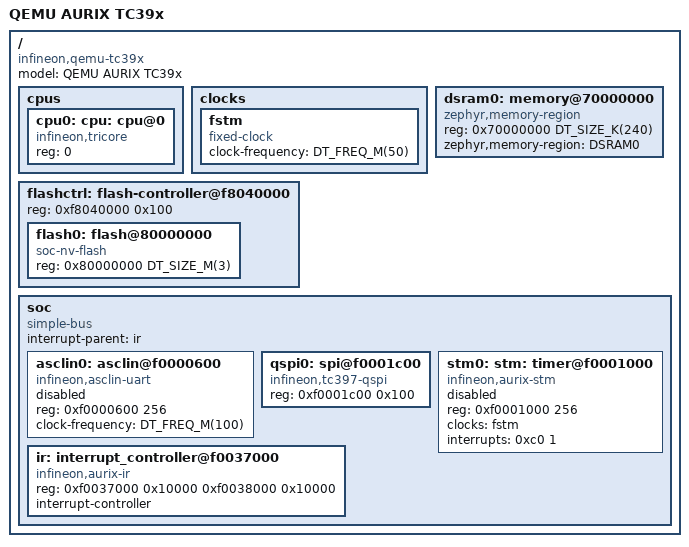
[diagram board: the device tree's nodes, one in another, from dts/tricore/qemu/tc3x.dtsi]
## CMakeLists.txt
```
# SPDX-License-Identifier: GPL-2.0-or-later
cmake_minimum_required(VERSION 3.20.0)
find_package(Zephyr REQUIRED HINTS $ENV{ZEPHYR_BASE})
project(vmcu)
target_include_directories(app PRIVATE include)
target_sources(app PRIVATE src/main.c lib/protocol.c lib/safety.c)
target_include_directories(app PRIVATE ${ZEPHYR_BASE}/drivers/can)
target_sources(app PRIVATE drivers/can_tc397.c src/vehicle_can.c lib/can_policy.c)

if(CONFIG_VMCU_SAFETY_SPI)
  target_sources(app PRIVATE drivers/spi_tc397.c)
endif()
```

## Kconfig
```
# SPDX-License-Identifier: GPL-2.0-or-later
mainmenu "Apollo TC397 vMCU"
# NUM_IRQS counts SRC entries, not the 256 CPU priority vectors.
config NUM_IRQS
    default 512 if SOC_QEMU_TC3X
config CAN_TC397
    bool "TC397 CAN0 node0"
    default y
    depends on CAN
    select CAN_MCAN
config VMCU_SAFETY_SPI
    bool "Use QSPI0 for SI safety transport"
    default n
    select SPI
source "Kconfig.zephyr"
```

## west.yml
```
# SPDX-License-Identifier: Apache-2.0
# Independent vMCU source pin; the Apollo Safety Island checkout stays unchanged.
manifest:
  version: "1.2"
  projects:
    - name: zephyr
      url: https://github.com/zephyrproject-rtos/zephyr
      revision: 894020886d647a5f9b8a58bdf2cb8c211a62716b
      path: zephyr
  self:
    path: zephyr_vmcu_src
```

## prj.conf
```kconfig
CONFIG_SERIAL=y
CONFIG_CONSOLE=y
CONFIG_UART_CONSOLE=y
CONFIG_PRINTK=y
CONFIG_SHELL=y
CONFIG_SHELL_BACKEND_SERIAL=y
CONFIG_SHELL_BACKEND_SERIAL_INTERRUPT_DRIVEN=n
CONFIG_SHELL_PROMPT_UART="vmcu> "
CONFIG_SHELL_STACK_SIZE=4096
CONFIG_MAIN_STACK_SIZE=4096
CONFIG_SYSTEM_WORKQUEUE_STACK_SIZE=2048
CONFIG_LOG=n
CONFIG_BOOT_BANNER=y
CONFIG_CAN=y
CONFIG_CAN_FD_MODE=y
CONFIG_SHELL_CMD_BUFF_SIZE=256
CONFIG_SHELL_BACKEND_SERIAL_RX_RING_BUFFER_SIZE=256
```

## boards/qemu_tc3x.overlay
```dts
/* SPDX-License-Identifier: Apache-2.0 */

/* CPU0, memory, STM0 and polling ASCLIN driver come from upstream qemu_tc3x. */
/ {
	aliases {
		vmcu-link = &asclin0;
		vmcu-safety = &asclin2;
		vmcu-port = &port0;
		vmcu-can = &can0;
	};
	chosen {
		zephyr,console = &asclin1;
		zephyr,shell-uart = &asclin1;
	};
	soc {
		can0: can@f0208200 {
			compatible = "infineon,tc397-mcan";
			reg = <0xf0208200 0x100>, <0xf0200000 0x8000>,
			      <0xf0208000 0x100>, <0xf0208100 0x100>;
			reg-names = "m_can", "message_ram", "common", "node";
			interrupts = <0x16c 13>, <0x16d 14>;
			interrupt-names = "int0", "int1";
			clock-frequency = <100000000>;
			bitrate = <500000>;
			bitrate-data = <2000000>;
			bosch,mram-cfg = <0 8 4 8 0 0 8 8>;
			status = "okay";
		};
		asclin2: asclin@f0000800 {
			compatible = "infineon,asclin-uart";
			reg = <0xf0000800 0x100>;
			clock-frequency = <100000000>;
			current-speed = <115200>;
			status = "okay";
		};
		/* Register-level TC397 PORT0 subset; no alternate-function/IRQ claims. */
		port0: gpio@f003a000 {
			compatible = "infineon,tc397-port";
			reg = <0xf003a000 0x100>;
			status = "okay";
		};
		asclin1: asclin@f0000700 {
			compatible = "infineon,asclin-uart";
			reg = <0xf0000700 0x100>;
			clock-frequency = <100000000>;
			current-speed = <115200>;
			status = "okay";
		};
	};
};

&asclin0 {
	current-speed = <115200>;
	status = "okay";
};
```

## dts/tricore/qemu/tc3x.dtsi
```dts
/*
 * SPDX-FileCopyrightText: Copyright (c) 2026 Infineon Technologies AG,
 * SPDX-FileCopyrightText: or an affiliate of Infineon Technologies AG. All rights reserved.
 * SPDX-FileCopyrightText: Copyright (c) 2026 Linumiz
 *
 * SPDX-License-Identifier: Apache-2.0
 */

#include <mem.h>
#include <freq.h>
#include <skeleton.dtsi>

/ {
	model = "QEMU AURIX TC39x";
	compatible = "infineon,qemu-tc39x";

	cpus {
		#address-cells = <1>;
		#size-cells = <0>;

		cpu0: cpu: cpu@0 {
			compatible = "infineon,tricore", "infineon,tc162";
			reg = <0>;
		};
	};

	clocks {
		fstm: fstm {
			compatible = "fixed-clock";
			clock-frequency = <DT_FREQ_M(50)>;
			#clock-cells = <0>;
		};
	};

	flashctrl: flash-controller@f8040000 {
		reg = <0xf8040000 0x100>;
		ranges;
		#address-cells = <1>;
		#size-cells = <1>;

		flash0: flash@80000000 {
			compatible = "soc-nv-flash";
			reg = <0x80000000 DT_SIZE_M(3)>;
			ranges = <0x0 0x80000000 DT_SIZE_M(3)>;
			#address-cells = <1>;
			#size-cells = <1>;
		};
	};

	dsram0: memory@70000000 {
		compatible = "zephyr,memory-region", "mmio-sram";
		reg = <0x70000000 DT_SIZE_K(240)>;
		zephyr,memory-region = "DSRAM0";
	};

	soc {
		#address-cells = <1>;
		#size-cells = <1>;
		interrupt-parent = <&ir>;
		compatible = "simple-bus";
		ranges;

		asclin0: asclin@f0000600 {
			compatible = "infineon,asclin-uart";
			reg = <0xf0000600 256>;
			clock-frequency = <DT_FREQ_M(100)>;
			status = "disabled";
		};

		qspi0: spi@f0001c00 {
			compatible = "infineon,tc397-qspi";
			reg = <0xf0001c00 0x100>;
			#address-cells = <1>;
			#size-cells = <0>;
		};

		stm0: stm: timer@f0001000 {
			compatible = "infineon,aurix-stm";
			reg = <0xf0001000 256>;
			clocks = <&fstm>;
			interrupts = <0xc0 1>;
			status = "disabled";
		};

		ir: interrupt_controller@f0037000 {
			compatible = "infineon,aurix-ir";
			reg = <0xf0037000 0x10000 0xf0038000 0x10000>;
			#address-cells = <0>;
			#interrupt-cells = <2>;
			interrupt-controller;
		};
	};
};
```

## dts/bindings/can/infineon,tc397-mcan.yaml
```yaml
# SPDX-License-Identifier: Apache-2.0
description: TC397 CAN0 node0 functional M_CAN integration
compatible: "infineon,tc397-mcan"
include: ["bosch,m_can-base.yaml"]
properties:
  reg:
    required: true
  reg-names:
    required: true
  interrupts:
    required: true
  interrupt-names:
    required: true
  clock-frequency:
    type: int
    required: true
```

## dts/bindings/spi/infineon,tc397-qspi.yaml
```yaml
description: Infineon TC397 QSPI master functional subset
compatible: "infineon,tc397-qspi"
include: spi-controller.yaml
properties:
  reg:
    required: true
```

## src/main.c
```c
/* SPDX-License-Identifier: GPL-2.0-or-later */
#include <errno.h>
#include <string.h>
#include <zephyr/device.h>
#include <zephyr/drivers/uart.h>
#include <zephyr/drivers/spi.h>
#include <zephyr/kernel.h>
#include <zephyr/shell/shell.h>
#include <zephyr/shell/shell_uart.h>
#include <zephyr/sys/sys_io.h>
#include "rpc.h"
#include "safety.h"
#include "control.h"
#include "vehicle_can.h"

/* Three independent paths: AP management, console, SI CL0 safety. */
static const struct device *const ap_link = DEVICE_DT_GET(DT_ALIAS(vmcu_link));
static const struct device *const safety_link = DEVICE_DT_GET(DT_ALIAS(vmcu_safety));
#define PORT0 DT_REG_ADDR(DT_ALIAS(vmcu_port))
#define PORT_OUT 0x00u
#define PORT_OMR 0x04u
#define PORT_IOCR0 0x10u
#define PORT_IOCR4 0x14u
#define PORT_IN 0x24u
#define GPIO_RESET_N BIT(3)
#define GPIO_WAKE BIT(4)

static struct vmcu_safety safety;
static bool monitor = true, awaiting;
static uint32_t ap_epoch, tx_sequence;
static struct vmcu_frame pending, reply;
static uint8_t pending_peer;
struct request { struct vmcu_frame frame; uint8_t peer; uint32_t guard; };
K_MUTEX_DEFINE(state_lock);
K_MUTEX_DEFINE(command_lock);
K_SEM_DEFINE(reply_ready, 0, 1);
K_MSGQ_DEFINE(commands, sizeof(struct request), 1, 4);

static const char *state_name(unsigned state)
{
    static const char *const names[] = { "WAIT", "BOOT", "RUN", "OFF", "DEGRADED" };
    return state < ARRAY_SIZE(names) ? names[state] : "UNKNOWN";
}

static const char *fault_name(unsigned reason)
{
    static const char *const names[] = { "NONE", "LINK_TIMEOUT", "PFDI_FAULT", "SOC_ERROR_STUCK" };
    return reason < ARRAY_SIZE(names) ? names[reason] : "UNKNOWN";
}

static const char *peer_name(uint8_t peer)
{
    return peer == VMCU_SI0 ? "SI0" : "AP";
}

static void transmit(const struct device *uart, const struct vmcu_frame *frame)
{
    uint8_t bytes[VMCU_FRAME_SIZE];
    vmcu_encode(bytes, frame);
    for (unsigned i = 0; i < sizeof(bytes); i++) {
        uart_poll_out(uart, bytes[i]);
    }
}

#ifdef CONFIG_VMCU_SAFETY_SPI
static const struct device *const spi_link = DEVICE_DT_GET(DT_NODELABEL(qspi0));
static const struct spi_config spi_config = { .frequency = 1000000, .operation = SPI_WORD_SET(8) };
static bool spi_synced, spi_level;
static uint32_t spi_retry, spi_reads, spi_acks, spi_errors, spi_requests, spi_activity;
extern uint32_t vmcu_spi_irq_count(const struct device *dev);
static int spi_frame(const struct vmcu_frame *out, struct vmcu_frame *in)
{
    uint8_t tx[VMCU_FRAME_SIZE] = { 0 }, rx[VMCU_FRAME_SIZE];
    if (out) { vmcu_encode(tx, out); }
    struct spi_buf tb = { .buf = tx, .len = sizeof(tx) };
    struct spi_buf rb = { .buf = rx, .len = sizeof(rx) };
    struct spi_buf_set ts = { .buffers = &tb, .count = 1 };
    struct spi_buf_set rs = { .buffers = &rb, .count = 1 };
    int rc = spi_transceive(spi_link, &spi_config, &ts, &rs);
    if (!rc && in && !vmcu_decode(rx, in)) {
        bool filler = true;
        for (unsigned i = 0; i < sizeof(rx); i++) { filler &= rx[i] == 0xff || rx[i] == 0; }
        if (filler) { return -ENODATA; }
        rc = -EBADMSG;
    }
    if (rc) { spi_errors++; spi_synced = false; spi_retry = k_uptime_get_32() + 100; }
    return rc;
}
#endif

static void receive(const struct vmcu_frame *frame, uint8_t peer, uint32_t now)
{
    uint32_t epoch = peer == VMCU_SI0 ? safety.epoch : ap_epoch;
    if (frame->sender != peer) {
        return;
    }
    if (frame->type == VMCU_REPLY) {
        if (awaiting && peer == pending_peer && frame->epoch == epoch &&
            frame->epoch == pending.epoch && frame->sequence == pending.sequence &&
            frame->progress == pending.progress && frame->flags <= VMCU_STALE) {
            reply = *frame;
            awaiting = false;
            k_sem_give(&reply_ready);
        }
    } else if (peer == VMCU_SI0) {
        (void)vmcu_safety_receive(&safety, frame, now);
    } else if (frame->type == VMCU_HELLO && frame->epoch &&
               !frame->flags && !frame->progress && !frame->argument &&
               (!ap_epoch || frame->epoch == ap_epoch || vmcu_newer(frame->epoch, ap_epoch))) {
        ap_epoch = frame->epoch;
        struct vmcu_frame ack = {
            .type = VMCU_HELLO_ACK, .sender = VMCU_MCU,
            .epoch = ap_epoch, .sequence = ++tx_sequence
        };
        transmit(ap_link, &ack);
    }
    /* AP HEALTH is deliberately not an input to the safety decision. */
}

#ifdef CONFIG_VMCU_SAFETY_SPI
static void spi_received(const struct vmcu_frame *frame, uint32_t now, bool request_seen)
{
    if (frame->sender != VMCU_SI0) { return; }
    if (!request_seen) {
        uint32_t deadline = k_uptime_get_32() + 1000;
        /* ACK must not release the retained toggle before GPIO transport sees it. */
        while (!!(sys_read32(PORT0 + PORT_IN) & BIT(5)) == spi_level) {
            if ((int32_t)(k_uptime_get_32() - deadline) >= 0) {
                spi_errors++;
                spi_synced = false;
                spi_retry = k_uptime_get_32() + 100;
                printk("VMCU_SPI error=request-timeout sequence=%u\n", frame->sequence);
                return;
            }
            k_sleep(K_MSEC(1));
        }
        spi_level = !spi_level;
        spi_requests++;
        spi_activity = k_uptime_get_32();
    }
    receive(frame, VMCU_SI0, now);
    spi_reads++;
    struct vmcu_frame ack = { .type = VMCU_SPI_ACK, .sender = VMCU_MCU,
        .epoch = frame->epoch, .sequence = frame->sequence, .progress = frame->type };
    if (!spi_frame(&ack, NULL)) {
        spi_acks++;
        printk("VMCU_SPI rx=%u ack=%u errors=%u epoch=%u sequence=%u type=%u\n",
               spi_reads, spi_acks, spi_errors, frame->epoch, frame->sequence, frame->type);
    }
}
#endif

static void link_worker(void *unused1, void *unused2, void *unused3)
{
    struct vmcu_stream streams[2] = { 0 };
    const struct device *const uart[] = { ap_link, safety_link };
    const uint8_t peer[] = { VMCU_AP, VMCU_SI0 };
    unsigned previous_state = SAFETY_WAIT, previous_fault = SAFETY_NONE;
    ARG_UNUSED(unused1); ARG_UNUSED(unused2); ARG_UNUSED(unused3);
    if (!device_is_ready(ap_link) ||
#ifdef CONFIG_VMCU_SAFETY_SPI
        !device_is_ready(spi_link)
#else
        !device_is_ready(safety_link)
#endif
        ) {
        printk("VMCU_INIT result=FAIL reason=uart-not-ready\n");
        return;
    }
    /* Establish the inactive reset latch BEFORE enabling its output driver.
     * IN[2] pulls up; IN[0:1] float. IOCR byte 0x80 selects push-pull GPIO.
     */
    sys_write32(GPIO_RESET_N, PORT0 + PORT_OUT);
    sys_write32(0x80100000u, PORT0 + PORT_IOCR0);
    sys_write32(0x00000080u, PORT0 + PORT_IOCR4);
#ifdef CONFIG_VMCU_SAFETY_SPI
    printk("VMCU_INIT result=PASS shell=ASCLIN1 management=ASCLIN0 safety=QSPI0 period_ms=5000\n");
#else
    printk("VMCU_INIT result=PASS shell=ASCLIN1 management=ASCLIN0 safety=ASCLIN2 period_ms=5000\n");
#endif
    printk("VMCU_STATE source=SI0_PFDI state=WAIT fault=NONE epoch=0\n");
    for (;;) {
        uint32_t now = k_uptime_get_32();
        struct request request;
        struct vmcu_safety changed;
        bool announce = false;
        k_mutex_lock(&state_lock, K_FOREVER);
        for (unsigned channel = 0; channel < ARRAY_SIZE(uart); channel++) {
#ifdef CONFIG_VMCU_SAFETY_SPI
            if (channel == 1) { continue; }
#endif
            unsigned char byte;
            struct vmcu_frame frame;
            for (unsigned i = 0; i < 128 && uart_poll_in(uart[channel], &byte) == 0; i++) {
                if (vmcu_feed(&streams[channel], byte, &frame)) {
                    receive(&frame, peer[channel], now);
                }
            }
        }
#ifdef CONFIG_VMCU_SAFETY_SPI
        if (spi_synced && now - spi_activity > 6000) { spi_synced = false; }
        bool level = !!(sys_read32(PORT0 + PORT_IN) & BIT(5));
        if (!spi_synced && (int32_t)(now - spi_retry) >= 0) {
            struct vmcu_frame sync = { .type = VMCU_SPI_SYNC, .sender = VMCU_MCU };
            spi_level = level;
            if (!spi_frame(&sync, NULL)) {
                spi_synced = true;
                spi_activity = now;
                printk("VMCU_SPI sync=sent\n");
            }
        } else if (spi_synced && level != spi_level) {
            struct vmcu_frame frame;
            spi_level = level;
            spi_requests++;
            spi_activity = now;
            int rc = spi_frame(NULL, &frame);
            if (!rc) { spi_received(&frame, now, true); }
            else if (rc == -ENODATA) { spi_synced = false; }

        }
#endif
        vmcu_safety_gpio(&safety, (sys_read32(PORT0 + PORT_IN) & BIT(0)) != 0, now);
        vmcu_safety_tick(&safety, now);
        if (safety.state != previous_state || safety.reason != previous_fault) {
            announce = monitor;
            changed = safety;
            previous_state = safety.state;
            previous_fault = safety.reason;
        }
        if (k_msgq_get(&commands, &request, K_NO_WAIT) == 0 && awaiting &&
            request.peer == pending_peer &&
            (!request.guard || (request.guard == safety.epoch &&
             now - safety.received_ms < VMCU_SAFETY_DEADLINE_MS)) && request.frame.epoch ==
            (request.peer == VMCU_SI0 ? safety.epoch : ap_epoch)) {
#ifdef CONFIG_VMCU_SAFETY_SPI
            if (request.peer == VMCU_SI0) {
                k_sleep(K_MSEC(20));
                struct vmcu_frame incoming;
                if (!spi_frame(&request.frame, &incoming)) {
                    spi_received(&incoming, now, false);
                }
            } else
#endif
            { transmit(request.peer == VMCU_SI0 ? safety_link : ap_link, &request.frame); }
        }
        k_mutex_unlock(&state_lock);
        if (announce) {
            shell_print(shell_backend_uart_get_ptr(),
                        "VMCU_STATE source=SI0_PFDI state=%s fault=%s epoch=%u pfdi_fault=0x%04x",
                        state_name(changed.state), fault_name(changed.reason), changed.epoch,
                        changed.fault);
        }
        k_sleep(K_MSEC(1));
    }
}
K_THREAD_DEFINE(link_thread, 4096, link_worker, NULL, NULL, NULL, 5, 0, 0);

/* command_lock serializes shell and vehicle requests; link_worker owns UART I/O. */
static int exchange(uint8_t peer, uint32_t epoch, uint32_t sequence,
                    uint32_t operation, uint32_t value, struct vmcu_frame *response, uint32_t guard)
{
    struct request request;
    k_sem_reset(&reply_ready);
    k_mutex_lock(&state_lock, K_FOREVER);
    if (epoch != (peer == VMCU_SI0 ? safety.epoch : ap_epoch) ||
        (guard && (guard != safety.epoch ||
                   k_uptime_get_32() - safety.received_ms >= VMCU_SAFETY_DEADLINE_MS))) {
        k_mutex_unlock(&state_lock);
        return -EAGAIN;
    }
    pending = (struct vmcu_frame) {
        .type = VMCU_COMMAND, .sender = VMCU_MCU, .epoch = epoch,
        .sequence = sequence, .progress = operation, .argument = value
    };
    pending_peer = peer;
    awaiting = true;
    request = (struct request) { .frame = pending, .peer = peer, .guard = guard };
    int rc = k_msgq_put(&commands, &request, K_NO_WAIT);
    k_mutex_unlock(&state_lock);
    if (!rc) { rc = k_sem_take(&reply_ready, K_MSEC(2000)); }
    k_mutex_lock(&state_lock, K_FOREVER);
    awaiting = false;
    if (!rc) { *response = reply; }
    k_msgq_purge(&commands);
    k_mutex_unlock(&state_lock);
    if (rc) { return -ETIMEDOUT; }
    static const int errors[] = { 0, -ENOTSUP, -EINVAL, -EAGAIN };
    return errors[response->flags];
}

int vmcu_control_at(uint8_t peer, uint32_t operation, uint32_t value,
                    struct vmcu_frame *response, uint32_t guard)
{
    struct vmcu_frame cursor;
    k_mutex_lock(&command_lock, K_FOREVER);
    k_mutex_lock(&state_lock, K_FOREVER);
    uint32_t epoch = peer == VMCU_SI0 ? safety.epoch : ap_epoch;
    k_mutex_unlock(&state_lock);
    int rc = epoch ? exchange(peer, epoch, 0, VMCU_OP_SESSION, 0, &cursor, guard) : -ENOTCONN;
    if (!rc) {
        uint32_t next = cursor.argument + 1;
        if (!next) { next = 1; }
        rc = exchange(peer, epoch, next, operation, value, response, guard);
    }
    k_mutex_unlock(&command_lock);
    return rc;
}

int vmcu_control(uint8_t peer, uint32_t operation, uint32_t value, struct vmcu_frame *response)
{
    return vmcu_control_at(peer, operation, value, response, 0);
}

void vmcu_snapshot(struct vmcu_safety *snapshot, uint32_t *gpio)
{
    k_mutex_lock(&state_lock, K_FOREVER);
    *snapshot = safety;
    *gpio = sys_read32(PORT0 + PORT_IN);
    k_mutex_unlock(&state_lock);
}

int vmcu_power_off(struct vmcu_frame *response, uint32_t guard)
{
    int rc = vmcu_control_at(VMCU_SI0, VMCU_OP_POWER_OFF, 1, response, guard);
    if (rc) { return rc; }
    rc = vmcu_control_at(VMCU_AP, VMCU_OP_POWER_OFF, 0, response, guard);
    /* Timeout is ambiguous: a late AP shutdown must retain the SI guard. */
    if (rc == -ENOTSUP || rc == -EINVAL || rc == -ENOTCONN) {
        struct vmcu_frame cancel;
        (void)vmcu_control_at(VMCU_SI0, VMCU_OP_POWER_OFF, 0, &cancel, guard);
    }
    return rc;
}

int vmcu_power_on(struct vmcu_frame *response, uint32_t guard)
{
    int rc = vmcu_control_at(VMCU_SI0, VMCU_OP_POWER_STATUS, 0, response, guard);
    if (rc) { return rc; }
    if (response->argument != 3) { return -EALREADY; }
    sys_write32(GPIO_WAKE << 16, PORT0 + PORT_OMR);
    k_sleep(K_MSEC(50));
    k_mutex_lock(&state_lock, K_FOREVER);
    if (guard && (guard != safety.epoch ||
                  k_uptime_get_32() - safety.received_ms >= VMCU_SAFETY_DEADLINE_MS)) {
        k_mutex_unlock(&state_lock);
        return -EAGAIN;
    }
    sys_write32(GPIO_WAKE, PORT0 + PORT_OMR);
    k_mutex_unlock(&state_lock);
    k_sleep(K_MSEC(100));
    sys_write32(GPIO_WAKE << 16, PORT0 + PORT_OMR);
    return vmcu_control_at(VMCU_SI0, VMCU_OP_POWER_STATUS, 0, response, guard);
}

static int report_rpc(const struct shell *shell, uint8_t peer, unsigned operation,
                      int rc, const struct vmcu_frame *response)
{
    static const char *const results[] = { "OK", "UNSUPPORTED", "INVALID", "STALE" };
    if (rc) {
        shell_error(shell, "VMCU_RPC peer=%s operation=%u result=ERROR errno=%d",
                    peer_name(peer), operation, rc);
    } else {
        shell_print(shell, "VMCU_RPC peer=%s operation=%u transaction=%u result=%s value=0x%08x",
                    peer_name(peer), operation, response->sequence, results[response->flags],
                    response->argument);
    }
    return rc;
}

static int rpc(const struct shell *shell, uint8_t peer, uint32_t operation, uint32_t value)
{
    struct vmcu_frame response = { 0 };
    int rc = vmcu_control(peer, operation, value, &response);
    return report_rpc(shell, peer, operation, rc, &response);
}

static int command(const struct shell *shell, size_t argc, char **argv)
{
#ifdef CONFIG_VMCU_SAFETY_SPI
    if (argc == 3 && !strcmp(argv[1], "spi") && !strcmp(argv[2], "status")) {
        shell_print(shell, "VMCU_SPI_STATUS frames=%u ack=%u irq=%u req=%u failures=%u",
                    spi_reads, spi_acks, vmcu_spi_irq_count(spi_link), spi_requests, spi_errors);
        return 0;
    }
#endif
    if (argc >= 2 && !strcmp(argv[1], "can")) {
        return vmcu_can_shell(shell, argc - 2, argv + 2);
    }
    if (argc == 3 && !strcmp(argv[1], "recover")) {
        if (!strcmp(argv[2], "start")) { return rpc(shell, VMCU_SI0, VMCU_OP_RECOVER, 0); }
        if (!strcmp(argv[2], "status")) { return rpc(shell, VMCU_SI0, VMCU_OP_RECOVERY_STATUS, 0); }
        return -EINVAL;
    }
    if (argc == 3 && !strcmp(argv[1], "power")) {
        struct vmcu_frame response = { 0 };
        if (!strcmp(argv[2], "status")) { return rpc(shell, VMCU_SI0, VMCU_OP_POWER_STATUS, 0); }
        int rc;
        if (!strcmp(argv[2], "off")) { rc = vmcu_power_off(&response, 0); }
        else if (!strcmp(argv[2], "on")) { rc = vmcu_power_on(&response, 0); }
        else { return -EINVAL; }
        return report_rpc(shell, VMCU_SI0, VMCU_OP_POWER_STATUS, rc, &response);
    }
    if (argc == 4 && !strcmp(argv[1], "pmic")) {
        int err = 0;
        unsigned long value = shell_strtoul(argv[3], 0, &err);
        if (err || value > 10) { return -EINVAL; }
        if (!strcmp(argv[2], "rail") && value < 9) { return rpc(shell, VMCU_SI0, VMCU_OP_PMIC_RAIL, value); }
        if (!strcmp(argv[2], "fault")) { return rpc(shell, VMCU_SI0, VMCU_OP_PMIC_FAULT, value); }
        return -EINVAL;
    }
    if (argc == 2 && !strcmp(argv[1], "status")) {
        struct vmcu_safety s;
        k_mutex_lock(&state_lock, K_FOREVER);
        s = safety;
        k_mutex_unlock(&state_lock);
        shell_print(shell, "VMCU_STATUS source=SI0_PFDI state=%s fault=%s epoch=%u sequence=%u period_ms=5000 age_ms=%u interval_ms=%u monitored=0x%04x online=0x%04x pfdi_fault=0x%04x off=0x%04x gpio_edges=%u",
                    state_name(s.state), fault_name(s.reason), s.epoch, s.sequence,
                    s.epoch ? k_uptime_get_32() - s.received_ms : 0, s.interval_ms,
                    s.monitored, s.online, s.fault, s.off, s.gpio_edges);
        return 0;
    }
    if (argc == 3 && !strcmp(argv[1], "monitor") &&
        (!strcmp(argv[2], "on") || !strcmp(argv[2], "off"))) {
        k_mutex_lock(&state_lock, K_FOREVER);
        monitor = !strcmp(argv[2], "on");
        k_mutex_unlock(&state_lock);
        shell_print(shell, "VMCU_MONITOR %s (state changes only)", argv[2]);
        return 0;
    }
    if (argc == 3 && (!strcmp(argv[1], "apollo") || !strcmp(argv[1], "safety"))) {
        uint8_t peer = !strcmp(argv[1], "safety") ? VMCU_SI0 : VMCU_AP;
        if (!strcmp(argv[2], "ping")) { return rpc(shell, peer, VMCU_OP_PING, 0); }
        if (!strcmp(argv[2], "status")) { return rpc(shell, peer, VMCU_OP_STATUS, 0); }
        if (peer == VMCU_SI0 && !strcmp(argv[2], "gpio")) { return rpc(shell, peer, VMCU_OP_GPIO, 0); }
    }
    if (argc == 3 && !strcmp(argv[1], "heartbeat") &&
        (!strcmp(argv[2], "on") || !strcmp(argv[2], "off"))) {
        return rpc(shell, VMCU_SI0, VMCU_OP_HEARTBEAT, !strcmp(argv[2], "on"));
    }
    if (argc >= 2 && !strcmp(argv[1], "workload")) {
        shell_error(shell, "VMCU_RPC result=UNSUPPORTED AP health is owned by the existing SI0 PFDI monitor");
        return -ENOTSUP;
    }
    if (argc == 3 && !strcmp(argv[1], "gpio") && !strcmp(argv[2], "status")) {
        shell_print(shell, "VMCU_GPIO in=0x%04x out=0x%04x SOC_ERROR=%u SOC_PWR_REQ=%u IST_DONE_N=%u SOC_RESET_N=%u MCU_SOC_WAKE=%u",
                    sys_read32(PORT0 + PORT_IN), sys_read32(PORT0 + PORT_OUT),
                    !!(sys_read32(PORT0 + PORT_IN) & BIT(0)), !!(sys_read32(PORT0 + PORT_IN) & BIT(1)),
                    !!(sys_read32(PORT0 + PORT_IN) & BIT(2)), !!(sys_read32(PORT0 + PORT_IN) & GPIO_RESET_N),
                    !!(sys_read32(PORT0 + PORT_IN) & GPIO_WAKE));
        return 0;
    }
    if (argc == 4 && !strcmp(argv[1], "gpio")) {
        uint32_t mask, value;
        if (!strcmp(argv[2], "reset") &&
            (!strcmp(argv[3], "assert") || !strcmp(argv[3], "release"))) {
            mask = GPIO_RESET_N;
            value = !strcmp(argv[3], "release") ? mask : mask << 16;
        } else if (!strcmp(argv[2], "wake") &&
                   (!strcmp(argv[3], "on") || !strcmp(argv[3], "off"))) {
            mask = GPIO_WAKE;
            value = !strcmp(argv[3], "on") ? mask : mask << 16;
        } else {
            return -EINVAL;
        }
        sys_write32(value, PORT0 + PORT_OMR);
        shell_print(shell, "VMCU_GPIO %s %s output=0x%04x", argv[2], argv[3], sys_read32(PORT0 + PORT_OUT));
        return 0;
    }
    shell_print(shell, "vmcu-cli status | monitor on|off | apollo ping|status | safety ping|status|gpio | heartbeat on|off | gpio status|reset assert|release|wake on|off | pmic rail|fault INDEX | recover start|status | power off|on|status | can status|restart|trace on|off|send ID FLAGS HEX");
    return -EINVAL;
}
/* Preserve standard iterable registration while allowing a hyphenated command. */
static const struct shell_static_entry vmcu_cli =
    SHELL_CMD_ARG(vmcu-cli, NULL, "SI CL0 PFDI safety monitor and GPIO controls", command, 1, 5);
static const TYPE_SECTION_ITERABLE(union shell_cmd_entry, shell_cmd_vmcu_cli,
                                  shell_root_cmds, shell_cmd_vmcu_cli) = { .entry = &vmcu_cli };

int main(void) { return 0; }
```

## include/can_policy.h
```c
/* SPDX-License-Identifier: GPL-2.0-or-later */
#ifndef VMCU_CAN_POLICY_H
#define VMCU_CAN_POLICY_H
#include <stdbool.h>
#include <stdint.h>
#define VMCU_CAN_COMMAND 0x600u
#define VMCU_CAN_REPLY 0x601u
#define VMCU_CAN_TELEMETRY 0x510u
#define VMCU_CAN_COMMAND_SIZE 24u
enum vehicle_result { VEHICLE_OK, VEHICLE_UNSUPPORTED, VEHICLE_INVALID, VEHICLE_STALE,
                      VEHICLE_IO, VEHICLE_UNAVAILABLE };
struct vehicle_session {
    uint32_t epoch, cookie, last;
    bool cached;
    uint8_t request[24], reply[24];
};
uint32_t vehicle_get32(const uint8_t *p);
void vehicle_put32(uint8_t *p, uint32_t value);
/* Returns 1 for a new command, 0 for a cached/rejected reply. */
int vehicle_request(struct vehicle_session *session, const uint8_t request[24],
                    uint8_t reply[24]);
void vehicle_complete(struct vehicle_session *session, const uint8_t request[24],
                      const uint8_t reply[24]);
#endif
```

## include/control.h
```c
/* SPDX-License-Identifier: GPL-2.0-or-later */
#ifndef VMCU_CONTROL_H
#define VMCU_CONTROL_H
#include "rpc.h"
#include "safety.h"
int vmcu_control(uint8_t peer, uint32_t operation, uint32_t value, struct vmcu_frame *response);
int vmcu_control_at(uint8_t peer, uint32_t operation, uint32_t value, struct vmcu_frame *response, uint32_t guard);
void vmcu_snapshot(struct vmcu_safety *snapshot, uint32_t *gpio);
int vmcu_power_off(struct vmcu_frame *response, uint32_t guard);
int vmcu_power_on(struct vmcu_frame *response, uint32_t guard);
#endif
```

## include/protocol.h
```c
/* SPDX-License-Identifier: GPL-2.0-or-later */
#ifndef VMCU_PROTOCOL_H
#define VMCU_PROTOCOL_H

#include <stdbool.h>
#include <stdint.h>

#define VMCU_FRAME_SIZE 28
#define VMCU_VERSION 1
#define VMCU_PERIOD_MS 100
#define VMCU_DEADLINE_MS 1000

enum vmcu_type {
    VMCU_HELLO = 1, VMCU_HELLO_ACK, VMCU_HEALTH, VMCU_STATUS,
    VMCU_COMMAND, VMCU_REPLY, VMCU_SAFETY_HEALTH, VMCU_SPI_ACK, VMCU_SPI_SYNC
};
enum vmcu_sender { VMCU_AP = 1, VMCU_MCU = 2, VMCU_SI0 = 3 };
enum vmcu_mode { VMCU_WAIT, VMCU_SYNC, VMCU_RUN, VMCU_DEGRADED };
enum vmcu_fault { VMCU_NONE, VMCU_LINK_TIMEOUT, VMCU_WORKLOAD_STALLED };

struct vmcu_frame {
    uint8_t type, sender, flags;
    uint32_t epoch, sequence, progress, argument;
};

struct vmcu_stream {
    uint8_t bytes[VMCU_FRAME_SIZE];
    unsigned used;
};

uint32_t vmcu_crc32(const uint8_t *bytes, unsigned length);
void vmcu_encode(uint8_t bytes[VMCU_FRAME_SIZE], const struct vmcu_frame *frame);
bool vmcu_decode(const uint8_t bytes[VMCU_FRAME_SIZE], struct vmcu_frame *frame);
bool vmcu_feed(struct vmcu_stream *stream, uint8_t byte, struct vmcu_frame *frame);
bool vmcu_newer(uint32_t candidate, uint32_t previous);

#endif
```

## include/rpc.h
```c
/* SPDX-License-Identifier: GPL-2.0-or-later */
#ifndef VMCU_RPC_H
#define VMCU_RPC_H

#include "protocol.h"

/* COMMAND/REPLY: sequence=transaction, progress=operation, argument=value.
 * REPLY flags=result. AP management supports ping/status, session discovery and poweroff.
 */
enum vmcu_operation {
    VMCU_OP_PING = 1, VMCU_OP_STATUS, VMCU_OP_HEARTBEAT,
    VMCU_OP_WORKLOAD, VMCU_OP_RESET, VMCU_OP_GPIO,
    VMCU_OP_SESSION, VMCU_OP_PMIC_RAIL, VMCU_OP_PMIC_FAULT,
    VMCU_OP_RECOVER, VMCU_OP_RECOVERY_STATUS, VMCU_OP_POWER_OFF,
    VMCU_OP_POWER_STATUS
};
enum vmcu_result {
    VMCU_OK, VMCU_UNSUPPORTED, VMCU_INVALID, VMCU_STALE
};

struct vmcu_rpc_peer {
    uint32_t epoch;
    bool have_transaction, poweroff_requested;
    struct vmcu_frame request, reply;
};

void vmcu_rpc_init(struct vmcu_rpc_peer *peer, uint32_t epoch);
/* False means an invalid sender/session or non-command: no response. */
bool vmcu_rpc_receive(struct vmcu_rpc_peer *peer,
                      const struct vmcu_frame *request,
                      struct vmcu_frame *reply);
#endif
```

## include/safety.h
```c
/* SPDX-License-Identifier: GPL-2.0-or-later */
#ifndef VMCU_SAFETY_H
#define VMCU_SAFETY_H

#include "protocol.h"

/* SI CL0 exports the existing AP PFDI monitor, not a synthetic workload. */
#define VMCU_SAFETY_PERIOD_MS 5000u
#define VMCU_SAFETY_DEADLINE_MS 15000u
#define VMCU_SOC_ERROR_DEADLINE_MS 1500u
#define VMCU_SAFETY_READY 1u
#define VMCU_SAFETY_FAULT 2u
#define VMCU_SAFETY_ALL_OFF 4u

enum vmcu_safety_state { SAFETY_WAIT, SAFETY_BOOT, SAFETY_RUN, SAFETY_OFF, SAFETY_DEGRADED };
enum vmcu_safety_fault { SAFETY_NONE, SAFETY_LINK_TIMEOUT, SAFETY_PFDI_FAULT, SAFETY_GPIO_STUCK };
struct vmcu_safety {
    uint32_t epoch, retired_epoch, sequence, received_ms, interval_ms;
    uint32_t gpio_edge_ms, gpio_edges, ready_since_ms, ready_edges;
    uint16_t monitored, online, fault, off;
    uint8_t flags;
    bool gpio_level, gpio_initialized, gpio_armed;
    enum vmcu_safety_state state;
    enum vmcu_safety_fault reason;
};

bool vmcu_safety_receive(struct vmcu_safety *state,
                         const struct vmcu_frame *frame, uint32_t now);
void vmcu_safety_gpio(struct vmcu_safety *state, bool level, uint32_t now);
void vmcu_safety_tick(struct vmcu_safety *state, uint32_t now);
#endif
```

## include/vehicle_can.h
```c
/* SPDX-License-Identifier: GPL-2.0-or-later */
#ifndef VMCU_VEHICLE_CAN_H
#define VMCU_VEHICLE_CAN_H
#include <zephyr/shell/shell.h>
int vmcu_can_shell(const struct shell *shell, size_t argc, char **argv);
#endif
```

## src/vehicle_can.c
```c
/* SPDX-License-Identifier: GPL-2.0-or-later */
#include <errno.h>
#include <string.h>
#include <zephyr/drivers/can.h>
#include <zephyr/kernel.h>
#include <zephyr/shell/shell_uart.h>
#include <zephyr/sys/atomic.h>
#include "can_policy.h"
#include "control.h"
#include "vehicle_can.h"

static const struct device *const bus = DEVICE_DT_GET(DT_ALIAS(vmcu_can));
static struct vehicle_session session;
static atomic_t rx_count, tx_count, tx_errors, rx_drops, trace;
K_MSGQ_DEFINE(received, sizeof(struct can_frame), 16, 4);

static void rx(const struct device *dev, struct can_frame *frame, void *arg)
{
    ARG_UNUSED(dev); ARG_UNUSED(arg);
    atomic_inc(&rx_count);
    if (k_msgq_put(&received, frame, K_NO_WAIT)) { atomic_inc(&rx_drops); }
}
static void tx_done(const struct device *dev, int error, void *arg)
{
    ARG_UNUSED(dev); ARG_UNUSED(arg);
    atomic_inc(error ? &tx_errors : &tx_count);
}
static int send(struct can_frame *frame)
{
    int rc = can_send(bus, frame, K_MSEC(100), tx_done, NULL);
    if (rc) { atomic_inc(&tx_errors); }
    return rc;
}
static uint8_t result(int rc)
{
    if (!rc) { return VEHICLE_OK; }
    if (rc == -ENOTSUP) { return VEHICLE_UNSUPPORTED; }
    if (rc == -EINVAL) { return VEHICLE_INVALID; }
    if (rc == -EAGAIN) { return VEHICLE_STALE; }
    if (rc == -ENOTCONN || rc == -EALREADY) { return VEHICLE_UNAVAILABLE; }
    return VEHICLE_IO;
}
static void dispatch(const struct can_frame *frame, const struct vmcu_safety *s)
{
    /* Other traffic is diagnostic only. BRS is optional; IDE/RTR/ESI are not commands. */
    if (frame->id != VMCU_CAN_COMMAND || frame->dlc != 12 ||
        (frame->flags & ~CAN_FRAME_BRS) != CAN_FRAME_FDF) { return; }
    struct can_frame response = { .id = VMCU_CAN_REPLY, .dlc = 12,
                                 .flags = CAN_FRAME_FDF | CAN_FRAME_BRS };
    if (vehicle_request(&session, frame->data, response.data)) {
        struct vmcu_frame reply = { 0 };
        int rc = 0;
        uint8_t op = frame->data[1];
        uint32_t arg = vehicle_get32(frame->data + 16);
        /* A stale safety channel must not authorize an actuator request. */
        if (op >= 5 && (!s->epoch || s->reason == SAFETY_LINK_TIMEOUT)) {
            rc = -ENOTCONN;
        } else {
            switch (op) {
            case 1: reply.argument = s->state; break;
            case 2: rc = vmcu_control_at(VMCU_AP, VMCU_OP_PING, 0, &reply, session.epoch); break;
            case 3: rc = vmcu_control_at(VMCU_SI0, VMCU_OP_PMIC_RAIL, arg, &reply, session.epoch); break;
            case 4: rc = vmcu_control_at(VMCU_SI0, VMCU_OP_PMIC_FAULT, arg, &reply, session.epoch); break;
            case 5: rc = vmcu_control_at(VMCU_SI0, VMCU_OP_RECOVER, 0, &reply, session.epoch); break;
            case 6: rc = vmcu_power_off(&reply, session.epoch); break;
            case 7: rc = vmcu_power_on(&reply, session.epoch); break;
            }
        }
        response.data[2] = result(rc);
        response.data[3] = s->state;
        vehicle_put32(response.data + 16, reply.argument);
        vehicle_complete(&session, frame->data, response.data);
        shell_print(shell_backend_uart_get_ptr(), "VMCU_CAN_COMMAND op=%u seq=%u result=%u value=0x%08x", op,
               session.last, response.data[2], reply.argument);
    }
    (void)send(&response);
}
static void telemetry(const struct vmcu_safety *s, uint32_t gpio)
{
    struct can_frame frame = { .id = VMCU_CAN_TELEMETRY, .dlc = 13,
                              .flags = CAN_FRAME_FDF | CAN_FRAME_BRS };
    frame.data[0] = 1; frame.data[1] = s->state;
    frame.data[2] = s->reason; frame.data[3] = gpio;
    vehicle_put32(frame.data + 4, s->epoch);
    vehicle_put32(frame.data + 8, session.cookie);
    vehicle_put32(frame.data + 12, s->sequence);
    vehicle_put32(frame.data + 16, s->monitored | (uint32_t)s->online << 16);
    vehicle_put32(frame.data + 20, s->fault | (uint32_t)s->off << 16);
    vehicle_put32(frame.data + 24, session.last);
    vehicle_put32(frame.data + 28, session.cookie ? 1 : 0);
    (void)send(&frame);
}
static void worker(void *a, void *b, void *c)
{
    ARG_UNUSED(a); ARG_UNUSED(b); ARG_UNUSED(c);
    if (!device_is_ready(bus)) { printk("VMCU_CAN_INIT result=FAIL reason=device\n"); return; }
    const struct can_filter standard = { .id = 0, .mask = 0 };
    const struct can_filter extended = { .id = 0, .mask = 0, .flags = CAN_FILTER_IDE };
    int rc = can_set_mode(bus, CAN_MODE_FD);
    int std_filter = can_add_rx_filter(bus, rx, NULL, &standard);
    int ext_filter = can_add_rx_filter(bus, rx, NULL, &extended);
    if (!rc && std_filter >= 0 && ext_filter >= 0) { rc = can_start(bus); }
    else if (!rc) { rc = -ENOSPC; }
    printk("VMCU_CAN_INIT result=%s errno=%d nominal=500000 data=2000000\n", rc ? "FAIL" : "PASS", rc);
    if (rc) { return; }
    uint32_t last_report = 0, last_session_try = 0;
    unsigned last_state = UINT32_MAX, last_fault = UINT32_MAX;
    for (;;) {
        struct vmcu_safety s;
        uint32_t gpio, now = k_uptime_get_32();
        vmcu_snapshot(&s, &gpio);
        if (session.epoch != s.epoch) { session = (struct vehicle_session) { .epoch = s.epoch }; }
        if (!session.cookie && s.epoch && now - last_session_try >= 1000) {
            struct vmcu_frame reply;
            last_session_try = now;
            if (!vmcu_control(VMCU_SI0, VMCU_OP_PING, 0, &reply) && reply.epoch == s.epoch) {
                session.cookie = reply.sequence;
                shell_print(shell_backend_uart_get_ptr(), "VMCU_CAN_SESSION epoch=%u cookie=%u", session.epoch, session.cookie);
            }
        }
        if (s.epoch && (now - last_report >= 5000 || s.state != last_state || s.reason != last_fault)) {
            telemetry(&s, gpio);
            last_report = now; last_state = s.state; last_fault = s.reason;
        }
        struct can_frame frame;
        if (!k_msgq_get(&received, &frame, K_MSEC(20))) {
            if (atomic_get(&trace)) {
                char hex[129];
                static const char digits[] = "0123456789abcdef";
                unsigned len = can_dlc_to_bytes(frame.dlc);
                for (unsigned i = 0; i < len; i++) {
                    hex[i * 2] = digits[frame.data[i] >> 4]; hex[i * 2 + 1] = digits[frame.data[i] & 15];
                }
                hex[len * 2] = 0;
                shell_print(shell_backend_uart_get_ptr(), "VMCU_CAN_RX id=0x%x flags=0x%x dlc=%u data=%s", frame.id, frame.flags, frame.dlc, hex);
            }
            vmcu_snapshot(&s, &gpio);
            if (session.epoch != s.epoch) { session = (struct vehicle_session) { .epoch = s.epoch }; }
            dispatch(&frame, &s);
        }
    }
}
K_THREAD_DEFINE(can_thread, 4096, worker, NULL, NULL, NULL, 7, 0, 0);

int vmcu_can_shell(const struct shell *shell, size_t argc, char **argv)
{
    if (!device_is_ready(bus)) { return -ENODEV; }
    if (argc == 1 && !strcmp(argv[0], "status")) {
        enum can_state state;
        struct can_bus_err_cnt errors;
        int rc = can_get_state(bus, &state, &errors);
        if (rc) { return rc; }
        shell_print(shell, "VMCU_CAN_STATUS state=%u rx=%ld tx=%ld tx_errors=%ld rx_drops=%ld tec=%u rec=%u",
                    state, (long)atomic_get(&rx_count), (long)atomic_get(&tx_count),
                    (long)atomic_get(&tx_errors), (long)atomic_get(&rx_drops), errors.tx_err_cnt, errors.rx_err_cnt);
        return 0;
    }
    if (argc == 1 && !strcmp(argv[0], "restart")) {
        int rc = can_stop(bus);
        if (rc && rc != -EALREADY) { return rc; }
        rc = can_start(bus);
        shell_print(shell, "VMCU_CAN_RESTART errno=%d", rc);
        return rc;
    }
    if (argc == 2 && !strcmp(argv[0], "trace") &&
        (!strcmp(argv[1], "on") || !strcmp(argv[1], "off"))) {
        atomic_set(&trace, !strcmp(argv[1], "on"));
        shell_print(shell, "VMCU_CAN_TRACE %s", argv[1]);
        return 0;
    }
    if (argc == 4 && !strcmp(argv[0], "send")) {
        int err = 0;
        unsigned long id = shell_strtoul(argv[1], 0, &err);
        unsigned long flags = shell_strtoul(argv[2], 0, &err);
        size_t len = strlen(argv[3]);
        if (err || flags & ~(CAN_FRAME_IDE | CAN_FRAME_FDF | CAN_FRAME_BRS) ||
            id > (flags & CAN_FRAME_IDE ? CAN_EXT_ID_MASK : CAN_STD_ID_MASK) ||
            ((flags & CAN_FRAME_BRS) && !(flags & CAN_FRAME_FDF)) || len % 2 || len > 128 ||
            (!(flags & CAN_FRAME_FDF) && len > 16)) { return -EINVAL; }
        struct can_frame frame = { .id = id, .flags = flags, .dlc = can_bytes_to_dlc(len / 2) };
        if (can_dlc_to_bytes(frame.dlc) != len / 2) { return -EINVAL; }
        for (unsigned i = 0; i < len / 2; i++) {
            char pair[3] = { argv[3][i * 2], argv[3][i * 2 + 1], 0 };
            frame.data[i] = shell_strtoul(pair, 16, &err);
            if (err) { return -EINVAL; }
        }
        int rc = send(&frame);
        shell_print(shell, "VMCU_CAN_SEND id=0x%x dlc=%u errno=%d", frame.id, frame.dlc, rc);
        return rc;
    }
    return -EINVAL;
}
```
